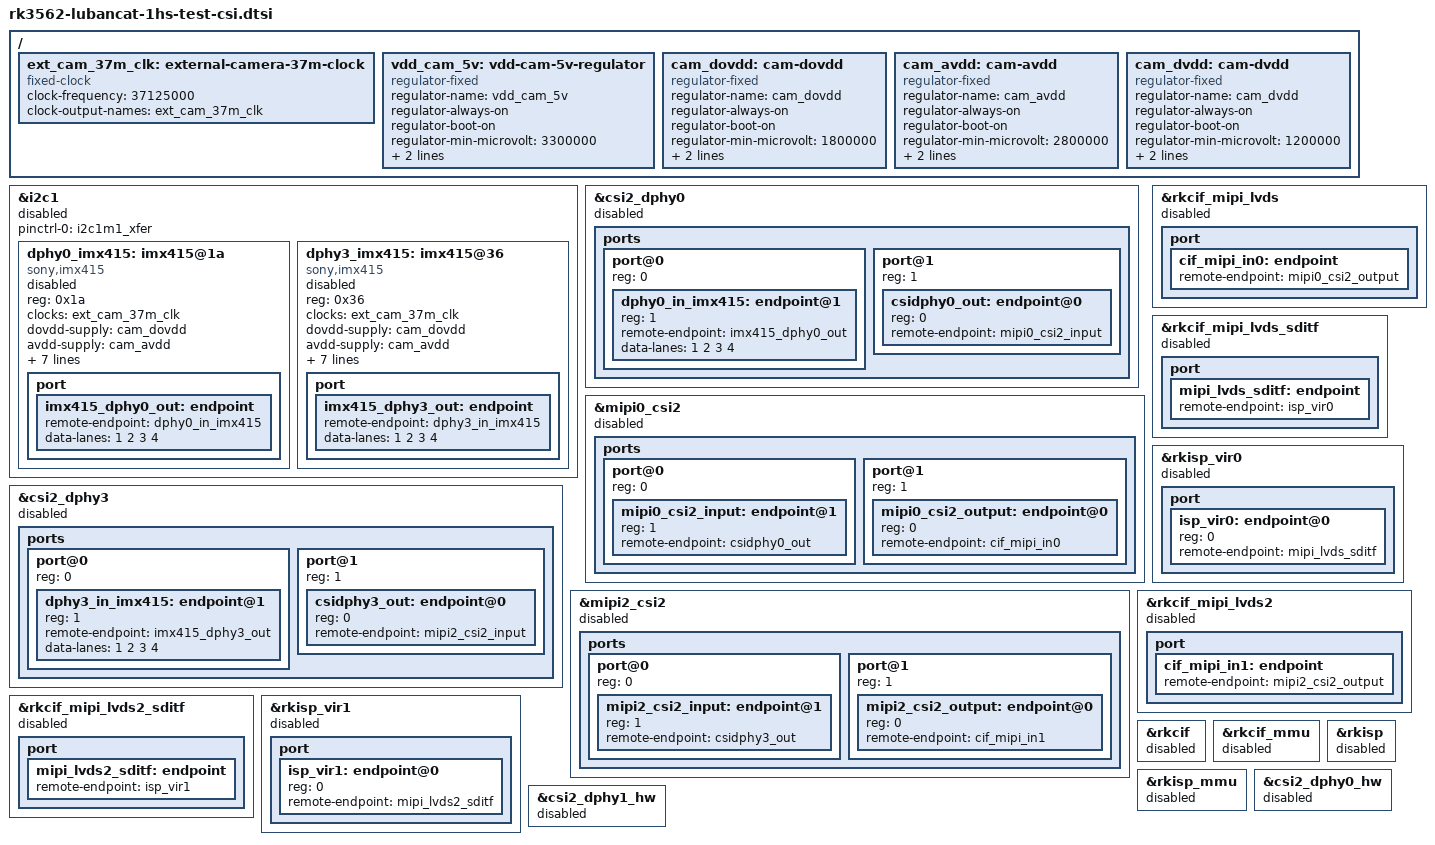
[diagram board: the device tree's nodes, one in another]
// SPDX-License-Identifier: (GPL-2.0+ OR MIT)
/*
 * Copyright (c) 2025 Rockchip Electronics Co., Ltd.
 *
 */
/ {
	ext_cam_37m_clk: external-camera-37m-clock {
		compatible = "fixed-clock";
		#clock-cells = <0>;
		clock-frequency = <37125000>;
		clock-output-names = "ext_cam_37m_clk";
	};

	vdd_cam_5v: vdd-cam-5v-regulator {
		compatible = "regulator-fixed";
		regulator-name = "vdd_cam_5v";
		regulator-always-on;
		regulator-boot-on;
		regulator-min-microvolt = <3300000>;
		regulator-max-microvolt = <3300000>;
		vin-supply = <&vdd_5v>;
	};

	cam_dovdd: cam-dovdd {
		compatible = "regulator-fixed";
		regulator-name = "cam_dovdd";
		regulator-always-on;
		regulator-boot-on;
		regulator-min-microvolt = <1800000>;
		regulator-max-microvolt = <1800000>;
		vin-supply = <&vdd_cam_5v>;
	};

	cam_avdd: cam-avdd {
		compatible = "regulator-fixed";
		regulator-name = "cam_avdd";
		regulator-always-on;
		regulator-boot-on;
		regulator-min-microvolt = <2800000>;
		regulator-max-microvolt = <2800000>;
		vin-supply = <&vdd_cam_5v>;
	};

	cam_dvdd: cam-dvdd {
		compatible = "regulator-fixed";
		regulator-name = "cam_dvdd";
		regulator-always-on;
		regulator-boot-on;
		regulator-min-microvolt = <1200000>;
		regulator-max-microvolt = <1200000>;
		vin-supply = <&vdd_cam_5v>;
	};
};

&i2c1 {
	status = "disabled";
	pinctrl-names = "default";
	pinctrl-0 = <&i2c1m1_xfer>;

	dphy0_imx415: imx415@1a {
		compatible = "sony,imx415";
		status = "disabled";
		reg = <0x1a>;
		clocks = <&ext_cam_37m_clk>;
		clock-names = "xvclk";
		dovdd-supply = <&cam_dovdd>;
		avdd-supply = <&cam_avdd>;
		dvdd-supply = <&cam_dvdd>;
		reset-gpios = <&gpio3 RK_PA0 GPIO_ACTIVE_LOW>;

		rockchip,camera-module-index = <0>;
		rockchip,camera-module-facing = "back";
		rockchip,camera-module-name = "CMK-OT2022-PX1";
		rockchip,camera-module-lens-name = "IR0147-50IRC-8M-F20-4k";
		// NO_HDR:0 HDR_X2:5 HDR_X3:6
		// rockchip,camera-hdr-mode = <0>;
		port {
			imx415_dphy0_out: endpoint {
				remote-endpoint = <&dphy0_in_imx415>;
				data-lanes = <1 2 3 4>;
			};
		};
	};

	dphy3_imx415: imx415@36 {
		compatible = "sony,imx415";
		status = "disabled";
		reg = <0x36>;
		clocks = <&ext_cam_37m_clk>;
		clock-names = "xvclk";
		dovdd-supply = <&cam_dovdd>;
		avdd-supply = <&cam_avdd>;
		dvdd-supply = <&cam_dvdd>;
		reset-gpios = <&gpio3 RK_PA1 GPIO_ACTIVE_LOW>;

		rockchip,camera-module-index = <1>;
		rockchip,camera-module-facing = "back";
		rockchip,camera-module-name = "CMK-OT2022-PX1";
		rockchip,camera-module-lens-name = "IR0147-50IRC-8M-F20-4k";
		// NO_HDR:0 HDR_X2:5 HDR_X3:6
		// rockchip,camera-hdr-mode = <0>;
		port {
			imx415_dphy3_out: endpoint {
				remote-endpoint = <&dphy3_in_imx415>;
				data-lanes = <1 2 3 4>;
			};
		};
	};
};

/* Link path: sensor->csi2_dphy0->mipi0_csi2->rkcif_mipi_lvds--->rkcif_mipi_lvds_sditf->rkisp_vir0 */
&csi2_dphy0 {
	status = "disabled";

	ports {
		#address-cells = <1>;
		#size-cells = <0>;
		port@0 {
			reg = <0>;
			#address-cells = <1>;
			#size-cells = <0>;

			dphy0_in_imx415: endpoint@1 {
				reg = <1>;
				remote-endpoint = <&imx415_dphy0_out>;
				data-lanes = <1 2 3 4>;
			};
		};

		port@1 {
			reg = <1>;
			#address-cells = <1>;
			#size-cells = <0>;

			csidphy0_out: endpoint@0 {
				reg = <0>;
				remote-endpoint = <&mipi0_csi2_input>;
			};
		};
	};
};

&mipi0_csi2 {
	status = "disabled";

	ports {
		#address-cells = <1>;
		#size-cells = <0>;

		port@0 {
			reg = <0>;
			#address-cells = <1>;
			#size-cells = <0>;

			mipi0_csi2_input: endpoint@1 {
				reg = <1>;
				remote-endpoint = <&csidphy0_out>;
			};
		};

		port@1 {
			reg = <1>;
			#address-cells = <1>;
			#size-cells = <0>;

			mipi0_csi2_output: endpoint@0 {
				reg = <0>;
				remote-endpoint = <&cif_mipi_in0>;
			};
		};
	};
};

&rkcif_mipi_lvds {
	status = "disabled";

	port {
		cif_mipi_in0: endpoint {
			remote-endpoint = <&mipi0_csi2_output>;
		};
	};
};

&rkcif_mipi_lvds_sditf {
	status = "disabled";

	port {
		mipi_lvds_sditf: endpoint {
			remote-endpoint = <&isp_vir0>;
		};
	};
};

&rkisp_vir0 {
	status = "disabled";

	port {
		#address-cells = <1>;
		#size-cells = <0>;

		isp_vir0: endpoint@0 {
			reg = <0>;
			remote-endpoint = <&mipi_lvds_sditf>;
		};
	};
};

/* Link path: sensor->csi2_dphy3->mipi2_csi2->rkcif_mipi_lvds2--->rkcif_mipi_lvds2_sditf->rkisp_vir1 */
&csi2_dphy3 {
	status = "disabled";

	ports {
		#address-cells = <1>;
		#size-cells = <0>;
		port@0 {
			reg = <0>;
			#address-cells = <1>;
			#size-cells = <0>;

			dphy3_in_imx415: endpoint@1 {
				reg = <1>;
				remote-endpoint = <&imx415_dphy3_out>;
				data-lanes = <1 2 3 4>;
			};
		};

		port@1 {
			reg = <1>;
			#address-cells = <1>;
			#size-cells = <0>;

			csidphy3_out: endpoint@0 {
				reg = <0>;
				remote-endpoint = <&mipi2_csi2_input>;
			};
		};
	};
};

&mipi2_csi2 {
	status = "disabled";

	ports {
		#address-cells = <1>;
		#size-cells = <0>;

		port@0 {
			reg = <0>;
			#address-cells = <1>;
			#size-cells = <0>;

			mipi2_csi2_input: endpoint@1 {
				reg = <1>;
				remote-endpoint = <&csidphy3_out>;
			};
		};

		port@1 {
			reg = <1>;
			#address-cells = <1>;
			#size-cells = <0>;

			mipi2_csi2_output: endpoint@0 {
				reg = <0>;
				remote-endpoint = <&cif_mipi_in1>;
			};
		};
	};
};


&rkcif_mipi_lvds2 {
	status = "disabled";

	port {
		cif_mipi_in1: endpoint {
			remote-endpoint = <&mipi2_csi2_output>;
		};
	};
};

&rkcif_mipi_lvds2_sditf {
	status = "disabled";

	port {
		mipi_lvds2_sditf: endpoint {
			remote-endpoint = <&isp_vir1>;
		};
	};
};

&rkisp_vir1 {
	status = "disabled";

	port {
		#address-cells = <1>;
		#size-cells = <0>;

		isp_vir1: endpoint@0 {
			reg = <0>;
			remote-endpoint = <&mipi_lvds2_sditf>;
		};
	};
};

&rkcif {
	status = "disabled";
};

&rkcif_mmu {
	status = "disabled";
};

&rkisp {
	status = "disabled";
};

&rkisp_mmu {
	status = "disabled";
};

&csi2_dphy0_hw {
	status = "disabled";
};

&csi2_dphy1_hw {
	status = "disabled";
};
